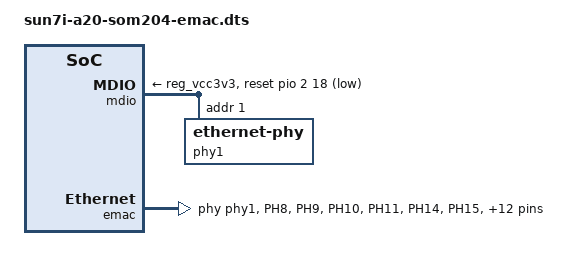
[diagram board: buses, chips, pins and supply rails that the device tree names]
/dts-v1/;
/plugin/;

/ {
	compatible = "olimex,a20-olimex-som204-evb",
		     "olimex,a20-olimex-som204-evb-emmc";
	description = "Use the second EMAC instead of the GMAC";

	fragment@0 {
		target = <&gmac>;
		__overlay__ {
			status = "disabled";
		};
	};

	fragment@1 {
		target = <&pio>;
		__overlay__ {
			emac_pins_b: emac0@1 {
				pins = "PH8", "PH9", "PH10", "PH11",
					"PH14", "PH15", "PH16", "PH17",
					"PH18", "PH19", "PH20", "PH21",
					"PH22", "PH23", "PH24", "PH25",
					"PH26", "PH27";
				function = "emac";
			};
		};
	};

	fragment@2 {
		target = <&mdio>;
		__overlay__ {
			phy-supply = <&reg_vcc3v3>;
			reset-gpios = <&pio 2 18 1>; /* PC18 */
			status = "okay";

			phy1: ethernet-phy@1 {
				reg = <1>;
			};
		};
	};

	fragment@3 {
		target = <&emac>;
		__overlay__ {
			pinctrl-names = "default";
			pinctrl-0 = <&emac_pins_b>;
			phy = <&phy1>;
			status = "okay";
		};
	};

	fragment@4 {
		target = <&emac_sram>;
		__overlay__ {
			status = "okay";
		};
	};
};
